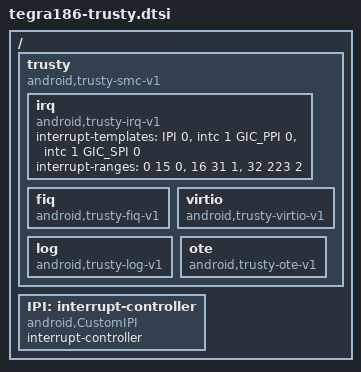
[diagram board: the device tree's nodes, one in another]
/*
 * Copyright (c) 2016, NVIDIA CORPORATION.  All rights reserved.
 *
 * This program is free software; you can redistribute it and/or modify
 * it under the terms of the GNU General Public License as published by
 * the Free Software Foundation; either version 2 of the License, or
 * (at your option) any later version.
 *
 * This program is distributed in the hope that it will be useful, but WITHOUT
 * ANY WARRANTY; without even the implied warranty of MERCHANTABILITY or
 * FITNESS FOR A PARTICULAR PURPOSE.  See the GNU General Public License for
 * more details.
 *
 * You should have received a copy of the GNU General Public License along
 * with this program; if not, write to the Free Software Foundation, Inc.,
 * 51 Franklin Street, Fifth Floor, Boston, MA  02110-1301, USA.
 */

/ {
	trusty {
		compatible = "android,trusty-smc-v1";
		ranges;
		#address-cells = <2>;
		#size-cells = <2>;

		irq {
			compatible = "android,trusty-irq-v1";
			interrupt-templates = <&IPI 0>,
					      <&intc 1 GIC_PPI 0>,
					      <&intc 1 GIC_SPI 0>;
			interrupt-ranges = < 0  15 0>,
					   <16  31 1>,
					   <32 223 2>;
		};

		fiq {
			compatible = "android,trusty-fiq-v1";
		};

		virtio {
			compatible = "android,trusty-virtio-v1";
		};

		log {
			compatible = "android,trusty-log-v1";
		};

                ote {
                        compatible = "android,trusty-ote-v1";
                };
	};

	IPI: interrupt-controller {
		compatible = "android,CustomIPI";
		#interrupt-cells = <1>;
		interrupt-controller;
	};
};
